# UPD70F3508 register map
Vendor: Renesas; Series: V850E2/Px4; File version: 1.0
CPU: other r0p0, little endian, no MPU, FPU, 4 interrupt priority bits
Registers are 8-bit, read-write, reset 0x0 unless marked. A register's access mark holds for its fields unless they carry their own. Offsets are from the block's base; [hi:lo] are bit positions; {n}, {i} and the like mark numbered series.

## DMAC — DMA Controller — 8-channel DMAC register block
Base 0xFFFF7300
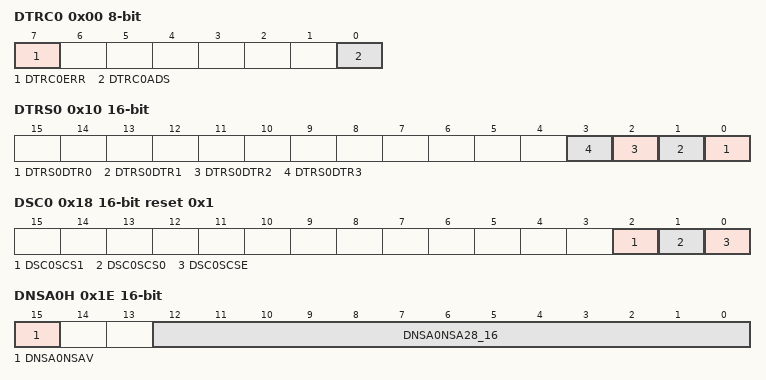
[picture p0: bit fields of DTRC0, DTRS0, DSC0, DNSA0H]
0x00 DTRC0 — DMA Transfer Request Control Register 0
  [7] DTRC0ERR — DMA transfer error status; write 0 to clear
  [0] DTRC0ADS — DMA transfer suspended; write 1 to request suspend
0x10 DTRS0 16-bit — DMA Transfer Request Select Register CH0
  [n] DTRS0DTR{n} (n=0..3) — DMA transfer request assignment bit {n}
{0x14+0x30*i} DSA{i}L 16-bit (i=0..7) — DMA Source Address Register L CH{i}
{0x16+0x30*i} DSA{i}H 16-bit (i=0..7) — DMA Source Address Register H CH{i}
0x18 DSC0 16-bit reset 0x1 — DMA Source Chip Select Register CH0
  [2] DSC0SCS1 — Source chip select bit 1
  [1] DSC0SCS0 — Source chip select bit 0
  [0] DSC0SCSE — Source chip select enable
{0x1C+0x30*i} DNSA{i}L 16-bit (i=0..7) — DMA Next Source Address Register L CH{i}
0x1E DNSA0H 16-bit — DMA Next Source Address Register H CH0
  [15] DNSA0NSAV — Next source address valid; copy on transfer completion
  [12:0] DNSA0NSA28_16 — Next source address bits 28:16
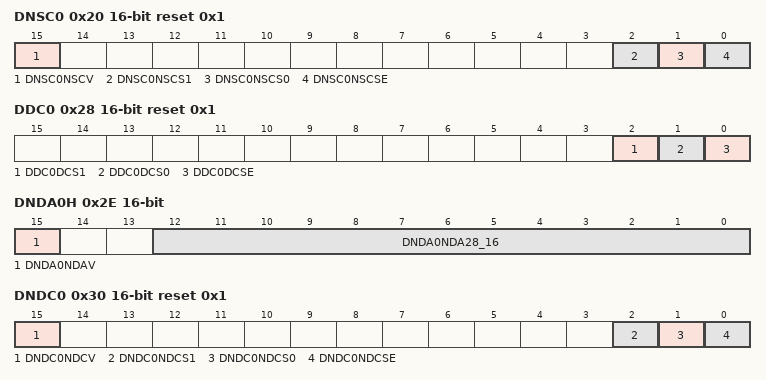
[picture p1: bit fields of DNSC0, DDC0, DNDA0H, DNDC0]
0x20 DNSC0 16-bit reset 0x1 — DMA Next Source Chip Select Register CH0
  [15] DNSC0NSCV — Next source chip select valid
  [2] DNSC0NSCS1 — Next source chip select bit 1
  [1] DNSC0NSCS0 — Next source chip select bit 0
  [0] DNSC0NSCSE — Next source chip select enable
{0x24+0x30*i} DDA{i}L 16-bit (i=0..7) — DMA Destination Address Register L CH{i}
{0x26+0x30*i} DDA{i}H 16-bit (i=0..7) — DMA Destination Address Register H CH{i}
0x28 DDC0 16-bit reset 0x1 — DMA Destination Chip Select Register CH0
  [2] DDC0DCS1 — Destination chip select bit 1
  [1] DDC0DCS0 — Destination chip select bit 0
  [0] DDC0DCSE — Destination chip select enable
{0x2C+0x30*i} DNDA{i}L 16-bit (i=0..7) — DMA Next Destination Address Register L CH{i}
0x2E DNDA0H 16-bit — DMA Next Destination Address Register H CH0
  [15] DNDA0NDAV — Next destination address valid; copy on transfer completion
  [12:0] DNDA0NDA28_16 — Next destination address bits 28:16
0x30 DNDC0 16-bit reset 0x1 — DMA Next Destination Chip Select Register CH0
  [15] DNDC0NDCV — Next destination chip select valid
  [2] DNDC0NDCS1 — Next destination chip select bit 1
  [1] DNDC0NDCS0 — Next destination chip select bit 0
  [0] DNDC0NDCSE — Next destination chip select enable
0x32 DTC0 16-bit — DMA Transfer Count Register CH0
  [14:0] DTC0DTC14_0 — DMA transfer count [14:0]; 0000H = 32768 transfers
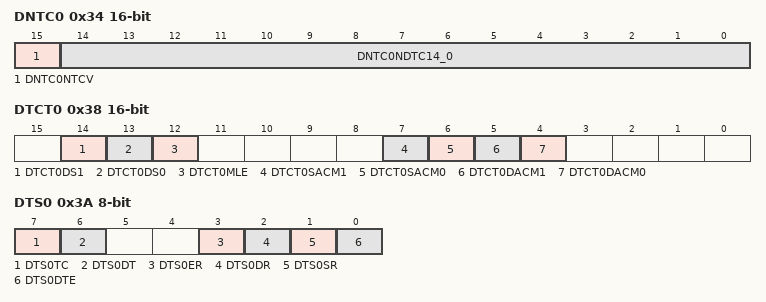
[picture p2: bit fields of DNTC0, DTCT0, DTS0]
0x34 DNTC0 16-bit — DMA Next Transfer Count Register CH0
  [15] DNTC0NTCV — Next transfer count valid
  [14:0] DNTC0NDTC14_0 — DMA next transfer count [14:0]
0x36 DTCC0 16-bit — DMA Transfer Count Compare Register CH0
  [14:0] DTCC0DTCC14_0 — Transfer count comparison value [14:0]; 0 = no compare
0x38 DTCT0 16-bit — DMA Transfer Control Register CH0
  [14] DTCT0DS1 — Transfer data size bit 1
  [13] DTCT0DS0 — Transfer data size bit 0
  [12] DTCT0MLE — Multi-link enable; 1 = do not clear DTSnDTE on completion
  [7] DTCT0SACM1 — Source address count direction bit 1
  [6] DTCT0SACM0 — Source address count direction bit 0
  [5] DTCT0DACM1 — Destination address count direction bit 1
  [4] DTCT0DACM0 — Destination address count direction bit 0
0x3A DTS0 — DMA Transfer Status Register CH0
  [7] DTS0TC — DMA transfer end status; write 0 to clear
  [6] DTS0DT — DMA transfer in progress
  [3] DTS0ER — DMA transfer error flag (read-only)
  [2] DTS0DR — Hardware DMA transfer request flag (read-only)
  [1] DTS0SR — Software DMA transfer request; write 1 to request
  [0] DTS0DTE — DMA transfer enable
0x40 DTRS1 16-bit — DMA Transfer Request Select Register CH1
  [3:0] DTRS1DTR3_0 — DMA transfer request assignment [3:0]
{0x18+0x30*i} DSC{i} 16-bit reset 0x1 (i=1..7) — DMA Source Chip Select Register CH{i}
{0x1E+0x30*i} DNSA{i}H 16-bit (i=1..7) — DMA Next Source Address Register H CH{i}
{0x20+0x30*i} DNSC{i} 16-bit reset 0x1 (i=1..7) — DMA Next Source Chip Select Register CH{i}
{0x28+0x30*i} DDC{i} 16-bit reset 0x1 (i=1..7) — DMA Destination Chip Select Register CH{i}
{0x2E+0x30*i} DNDA{i}H 16-bit (i=1..7) — DMA Next Destination Address Register H CH{i}
{0x30+0x30*i} DNDC{i} 16-bit reset 0x1 (i=1..7) — DMA Next Destination Chip Select Register CH{i}
{0x32+0x30*i} DTC{i} 16-bit (i=1..7) — DMA Transfer Count Register CH{i}
{0x34+0x30*i} DNTC{i} 16-bit (i=1..7) — DMA Next Transfer Count Register CH{i}
{0x36+0x30*i} DTCC{i} 16-bit (i=1..7) — DMA Transfer Count Compare Register CH{i}
{0x38+0x30*i} DTCT{i} 16-bit (i=1..7) — DMA Transfer Control Register CH{i}
{0x3A+0x30*i} DTS{i} (i=1..7) — DMA Transfer Status Register CH{i}
{0x10+0x30*i} DTRS{i} 16-bit (i=2..7) — DMA Transfer Request Select Register CH{i}
